# STM32F479 register map
File version: 2.0
CPU: CM4 r0p1, little endian, MPU, FPU, 4 interrupt priority bits
Registers are 32-bit, read-write, reset 0x0 unless marked. A register's access mark holds for its fields unless they carry their own. Offsets are from the block's base; [hi:lo] are bit positions.

## Ethernet_MMC — Ethernet: MAC management counters
Base 0x40028100
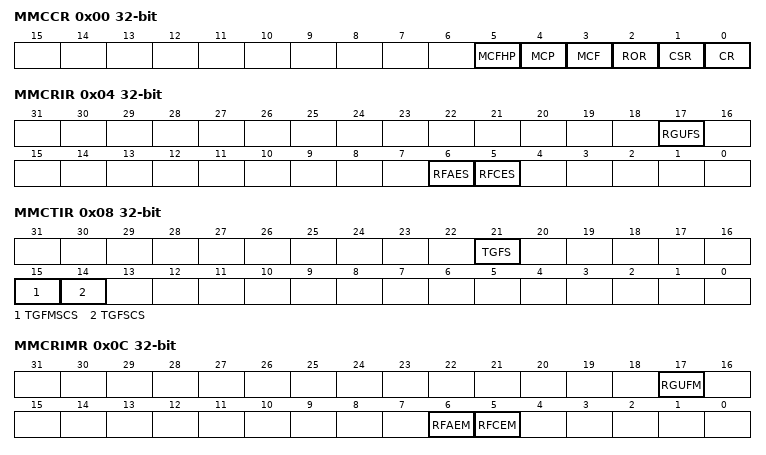
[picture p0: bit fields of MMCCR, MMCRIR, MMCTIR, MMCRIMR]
0x00 MMCCR — Ethernet MMC control register
  [5] MCFHP, [4] MCP, [3] MCF, [2] ROR, [1] CSR, [0] CR
0x04 MMCRIR — Ethernet MMC receive interrupt register
  [17] RGUFS, [6] RFAES, [5] RFCES
0x08 MMCTIR ro — Ethernet MMC transmit interrupt register
  [21] TGFS, [15] TGFMSCS, [14] TGFSCS
0x0C MMCRIMR — Ethernet MMC receive interrupt mask register
  [17] RGUFM, [6] RFAEM, [5] RFCEM
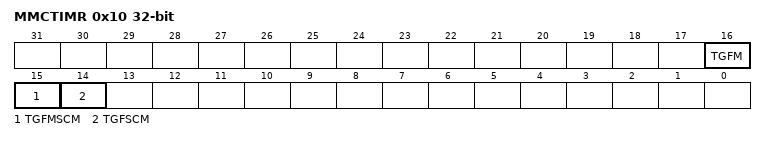
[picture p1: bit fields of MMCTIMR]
0x10 MMCTIMR — Ethernet MMC transmit interrupt mask register
  [16] TGFM, [15] TGFMSCM, [14] TGFSCM
0x4C MMCTGFSCCR ro — Ethernet MMC transmitted good frames after a single collision counter
  [31:0] TGFSCC
0x50 MMCTGFMSCCR ro — Ethernet MMC transmitted good frames after more than a single collision
  [31:0] TGFMSCC
0x68 MMCTGFCR ro — Ethernet MMC transmitted good frames counter register
  [31:0] TGFC — HTL
0x94 MMCRFCECR ro — Ethernet MMC received frames with CRC error counter register
  [31:0] RFCFC
0x98 MMCRFAECR ro — Ethernet MMC received frames with alignment error counter register
  [31:0] RFAEC
0xC4 MMCRGUFCR ro — MMC received good unicast frames counter register
  [31:0] RGUFC

## Ethernet_PTP — Ethernet: Precision time protocol
Base 0x40028700
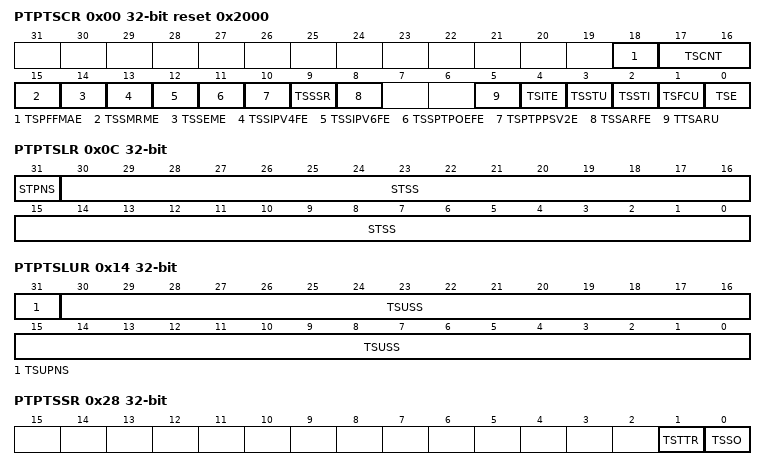
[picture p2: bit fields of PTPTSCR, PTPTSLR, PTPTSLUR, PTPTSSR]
0x00 PTPTSCR reset 0x2000 — Ethernet PTP time stamp control register
  [18] TSPFFMAE, [17:16] TSCNT, [15] TSSMRME, [14] TSSEME, [13] TSSIPV4FE, [12] TSSIPV6FE, [11] TSSPTPOEFE, [10] TSPTPPSV2E, [9] TSSSR, [8] TSSARFE, [5] TTSARU, [4] TSITE, [3] TSSTU, [2] TSSTI, [1] TSFCU, [0] TSE
0x04 PTPSSIR — Ethernet PTP subsecond increment register
  [7:0] STSSI
0x08 PTPTSHR ro — Ethernet PTP time stamp high register
  [31:0] STS
0x0C PTPTSLR ro — Ethernet PTP time stamp low register
  [31] STPNS, [30:0] STSS
0x10 PTPTSHUR — Ethernet PTP time stamp high update register
  [31:0] TSUS
0x14 PTPTSLUR — Ethernet PTP time stamp low update register
  [31] TSUPNS, [30:0] TSUSS
0x18 PTPTSAR — Ethernet PTP time stamp addend register
  [31:0] TSA
0x1C PTPTTHR — Ethernet PTP target time high register
  [31:0] TTSH — 0
0x20 PTPTTLR — Ethernet PTP target time low register
  [31:0] TTSL
0x28 PTPTSSR ro — Ethernet PTP time stamp status register
  [1] TSTTR, [0] TSSO
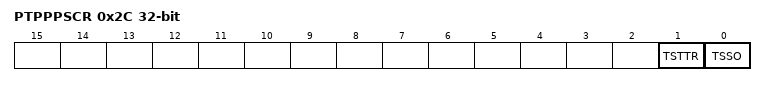
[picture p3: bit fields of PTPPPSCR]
0x2C PTPPPSCR ro — Ethernet PTP PPS control register
  [1] TSTTR, [0] TSSO

## FLASH
Base 0x40023C00
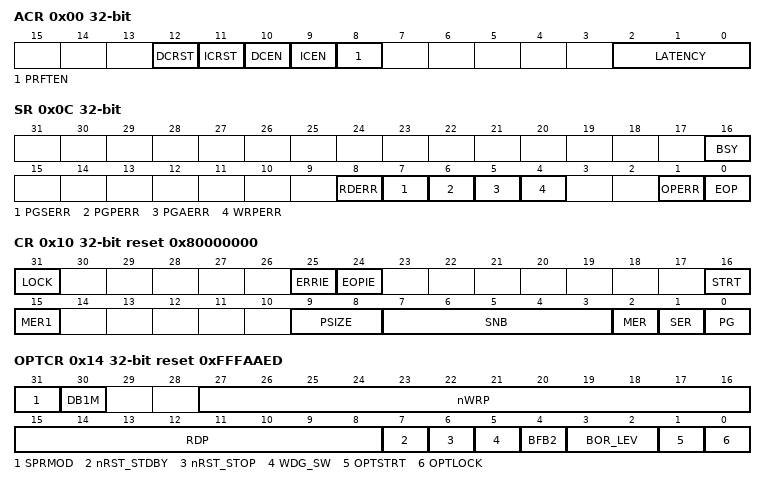
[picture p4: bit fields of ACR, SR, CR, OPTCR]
0x00 ACR access per field — Flash access control register
  [12] DCRST rw — Data cache reset
  [11] ICRST wo — Instruction cache reset
  [10] DCEN rw — Data cache enable
  [9] ICEN rw — Instruction cache enable
  [8] PRFTEN rw — Prefetch enable
  [2:0] LATENCY rw
0x04 KEYR wo — Flash key register
  [31:0] KEY — FPEC key
0x08 OPTKEYR wo — Flash option key register
  [31:0] OPTKEY — Option byte key
0x0C SR access per field — Status register
  [16] BSY ro — Busy
  [8] RDERR rw — Proprietary readout protection (PCROP) error
  [7] PGSERR rw — Programming sequence error
  [6] PGPERR rw — Programming parallelism error
  [5] PGAERR rw — Programming alignment error
  [4] WRPERR rw — Write protection error
  [1] OPERR rw — Operation error
  [0] EOP rw — End of operation
0x10 CR reset 0x80000000 — Control register
  [31] LOCK
  [25] ERRIE — Error interrupt enable
  [24] EOPIE — End of operation interrupt enable
  [16] STRT — Start
  [15] MER1 — Mass Erase of sectors 12 to 23
  [9:8] PSIZE — Program size
  [7:3] SNB — Sector number
  [2] MER — Mass Erase of sectors 0 to 11
  [1] SER — Sector Erase
  [0] PG — Programming
0x14 OPTCR reset 0xFFFAAED — Flash option control register
  [31] SPRMOD — Selection of protection mode for nWPRi bits
  [30] DB1M — Dual-bank on 1 Mbyte Flash memory devices
  [27:16] nWRP — Not write protect
  [15:8] RDP — Read protect
  [7] nRST_STDBY — nRST_STDBY User option bytes
  [6] nRST_STOP — nRST_STOP User option bytes
  [5] WDG_SW — WDG_SW User option bytes
  [4] BFB2 — Dual-bank Boot option byte
  [3:2] BOR_LEV — BOR reset Level
  [1] OPTSTRT — Option start
  [0] OPTLOCK — Option lock
0x18 OPTCR1 reset 0xFFF0000 — Flash option control register 1
  [27:16] nWRP — Not write protect
